# RockChip_RK3588 register map
Vendor: RockChip Electronics Co., Ltd.; Series: RK3588; File version: 0.1
Registers are 32-bit, read-write, no defined reset value unless marked. A register's access mark holds for its fields unless they carry their own. Offsets are from the block's base; [hi:lo] are bit positions; 'fields as' and 'values as' point back to an identical list; <NAME> marks a mode.

## CRU_DDRPHY3
Base 0xFD80C000
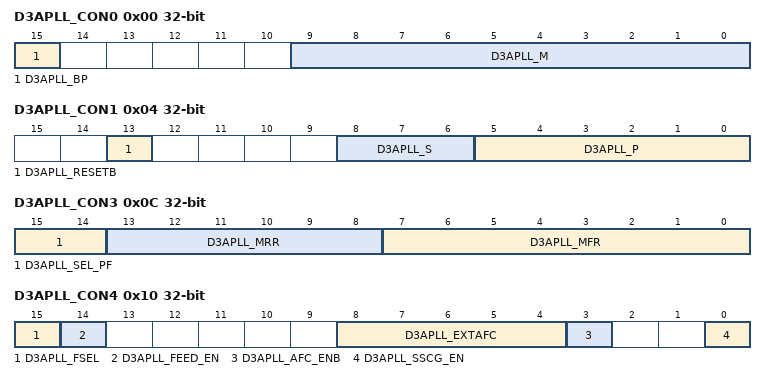
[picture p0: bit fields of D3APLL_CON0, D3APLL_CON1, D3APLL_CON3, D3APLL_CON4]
0x00 D3APLL_CON0 — D3APLL configuration register 0
  [15] D3APLL_BP — BYPASS: Bypass mode control signal.
    1=BYPASS (bypass mode is enabled. (FOUT = FIN).); 0=NORMAL (PLL operates normally.)
  [9:0] D3APLL_M — M: Division value of the 10-bit programmable main-divider. PLL has to be reset if M value is changed. 64 <= pll_m <= 1023
0x04 D3APLL_CON1 — D3APLL configuration register 1
  [13] D3APLL_RESETB — RESETB: Power down control signal.
    0=NORMAL (RESETB=0 from 1, PLL starts its normal operation after lock time.); 1=POWER_DOWN (RESETB=1, power down mode is enabled and all digital blocks are reset.)
  [8:6] D3APLL_S — Division value of the 3-bit programmable scaler. 0 <= pll_s <= 6
  [5:0] D3APLL_P — P: Division value of the 6-bit programmable pre-divider. PLL has to be reset if P value is changed. 1 <= pll_p <= 63
0x08 D3APLL_CON2 — D3APLL configuration register 2
  [15:0] D3APLL_K — K: Value of 16-bit DSM. pll_k[15:0] is a two's complement integer.
0x0C D3APLL_CON3 — D3APLL configuration register 3
  [15:14] D3APLL_SEL_PF — SEL_PF: Value of 2-bit modulation method control.
    0=DOWN_SPREAD; 1=UP_SPREAD; 2=CENTER_SPREAD2 (PLL has to be reset if pll_sel_pf is changed.); 3=CENTER_SPREAD3 (PLL has to be reset if pll_sel_pf is changed.)
  [13:8] D3APLL_MRR — MRR: Value of 6-bit modulation rate control. PLL has to be reset if pll_mrr is changed.
  [7:0] D3APLL_MFR — MFR: Value of 8-bit modulation frequency control. PLL has to be reset if pll_mfr is changed.
0x10 D3APLL_CON4 — D3APLL configuration register 4
  [15] D3APLL_FSEL — FSEL: Monitoring pin.
    0=FREF (FEED_OUT = FREF.); 1=FEED (FEED_OUT = FEED.)
  [14] D3APLL_FEED_EN — FEED_EN: Monitoring pin.
    0=DISABLED (FEED_OUT is disabled.); 1=ENABLED (FEED_OUT is enabled.)
  [8:4] D3APLL_EXTAFC — EXTAFC: Monitoring pin. If pll_afc_enb=1, AFC is disabled and VCO is calibrated manually by pll_extafc[4:0] for the test of VCO range.
  [3] D3APLL_AFC_ENB — AFC_ENB: Monitoring pin.
    0=ENABLED (AFC is enabled and VCO is calibrated automatically.); 1=DISABLED (AFC is disabled and VCO is calibrated manually by pll_extafc[4:0] for the test of VCO range.)
  [0] D3APLL_SSCG_EN — SSCG_EN: Enable pin for dithered mode.
    0=DISABLE (disable dithered mode.); 1=ENABLE (enable dithered mode.)
0x14 D3APLL_CON5 — D3APLL configuration register 5
  [0] D3APLL_FOUT_MASK — FOUT_MASK: Scaler's re-initialization time control pin.
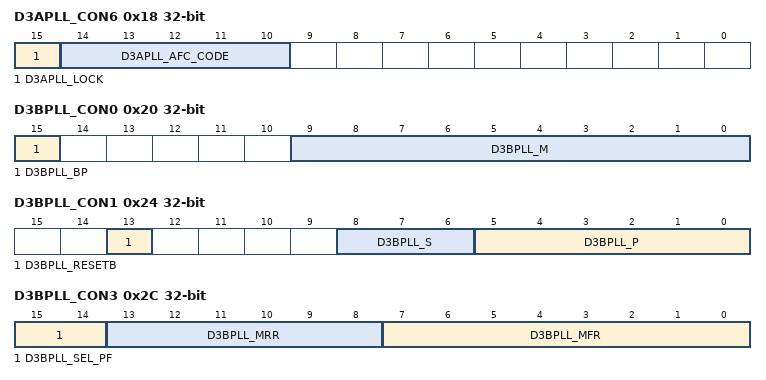
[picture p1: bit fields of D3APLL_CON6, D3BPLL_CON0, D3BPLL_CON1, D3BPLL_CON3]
0x18 D3APLL_CON6 — D3APLL configuration register 6
  [15] D3APLL_LOCK — LOCK: PLL lock flag.
    0=UNLOCKED (PLL is unlocked.); 1=LOCKED (PLL is locked.)
  [14:10] D3APLL_AFC_CODE — AFC_CODE: Monitoring pin. Output code of AFC(5 bits).
0x20 D3BPLL_CON0 — D3BPLL configuration register 0
  [15] D3BPLL_BP — BYPASS: Bypass mode control signal.
    values as D3APLL_CON0.D3APLL_BP
  [9:0] D3BPLL_M — M: Division value of the 10-bit programmable main-divider. PLL has to be reset if M value is changed. 64 <= pll_m <= 1023
0x24 D3BPLL_CON1 — D3BPLL configuration register 1
  [13] D3BPLL_RESETB — RESETB: Power down control signal.
    values as D3APLL_CON1.D3APLL_RESETB
  [8:6] D3BPLL_S — Division value of the 3-bit programmable scaler. 0 <= pll_s <= 6
  [5:0] D3BPLL_P — P: Division value of the 6-bit programmable pre-divider. PLL has to be reset if P value is changed. 1 <= pll_p <= 63
0x28 D3BPLL_CON2 — D3BPLL configuration register 2
  [15:0] D3BPLL_K — K: Value of 16-bit DSM. pll_k[15:0] is a two's complement integer.
0x2C D3BPLL_CON3 — D3BPLL configuration register 3
  [15:14] D3BPLL_SEL_PF — SEL_PF: Value of 2-bit modulation method control.
    values as D3APLL_CON3.D3APLL_SEL_PF
  [13:8] D3BPLL_MRR — MRR: Value of 6-bit modulation rate control. PLL has to be reset if pll_mrr is changed.
  [7:0] D3BPLL_MFR — MFR: Value of 8-bit modulation frequency control. PLL has to be reset if pll_mfr is changed.
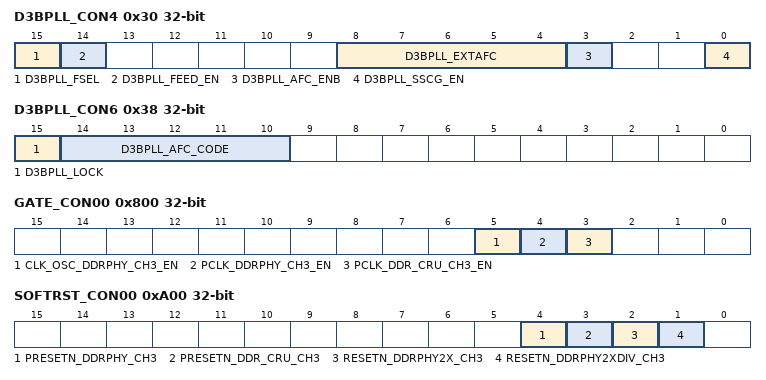
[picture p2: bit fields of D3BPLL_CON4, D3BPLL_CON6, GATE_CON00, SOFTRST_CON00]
0x30 D3BPLL_CON4 — D3BPLL configuration register 4
  [15] D3BPLL_FSEL — FSEL: Monitoring pin.
    0=FREF (FEED_OUT = FREF.); 1=FEED (FEED_OUT = FEED.)
  [14] D3BPLL_FEED_EN — FEED_EN: Monitoring pin.
    values as D3APLL_CON4.D3APLL_FEED_EN
  [8:4] D3BPLL_EXTAFC — EXTAFC: Monitoring pin. If pll_afc_enb=1, AFC is disabled and VCO is calibrated manually by pll_extafc[4:0] for the test of VCO range.
  [3] D3BPLL_AFC_ENB — AFC_ENB: Monitoring pin.
    values as D3APLL_CON4.D3APLL_AFC_ENB
  [0] D3BPLL_SSCG_EN — SSCG_EN: Enable pin for dithered mode.
    values as D3APLL_CON4.D3APLL_SSCG_EN
0x34 D3BPLL_CON5 — D3BPLL configuration register 5
  [0] D3BPLL_FOUT_MASK — FOUT_MASK: Scaler's re-initialization time control pin.
0x38 D3BPLL_CON6 — D3BPLL configuration register 6
  [15] D3BPLL_LOCK — LOCK: PLL lock flag.
    0=UNLOCKED (PLL is unlocked.); 1=LOCKED (PLL is locked.)
  [14:10] D3BPLL_AFC_CODE — AFC_CODE: Monitoring pin. Output code of AFC(5 bits).
0x300 CLKSEL_CON0 — Internal clock select and division register 0
  [0] CLK_DDRPHY2X_CH3_SEL — clk_ddrphy2x_ch3 clock mux.
    0=CLK_D3APLL_T; 1=CLK_D3BPLL
0x800 GATE_CON00 — Internal clock gate and division register 0
  [all] fields
    0=ENABLE; 1=DISABLE
  [5] CLK_OSC_DDRPHY_CH3_EN — clk_osc_ddrphy_ch3 clock gating control.
  [4] PCLK_DDRPHY_CH3_EN — pclk_ddrphy_ch3 clock gating control.
  [3] PCLK_DDR_CRU_CH3_EN — pclk_ddr_cru_ch3 clock gating control.
0xA00 SOFTRST_CON00 — Internal clock reset register 0
  [4] PRESETN_DDRPHY_CH3 — When high, reset relative logic
  [3] PRESETN_DDR_CRU_CH3 — When high, reset relative logic
  [2] RESETN_DDRPHY2X_CH3 — When high, reset relative logic
  [1] RESETN_DDRPHY2XDIV_CH3 — div_rst_n at ddr ch3 When high, reset relative logic
